# ISD91200B_v1 register map
File version: 1.0
Registers are 32-bit, read-write, reset 0x0 unless marked. A register's access mark holds for its fields unless they carry their own. Offsets are from the block's base; [hi:lo] are bit positions; {n}, {i} and the like mark numbered series; 'fields as' and 'values as' point back to an identical list.

## SARADC — SARADC Register Map
Base 0x40060000
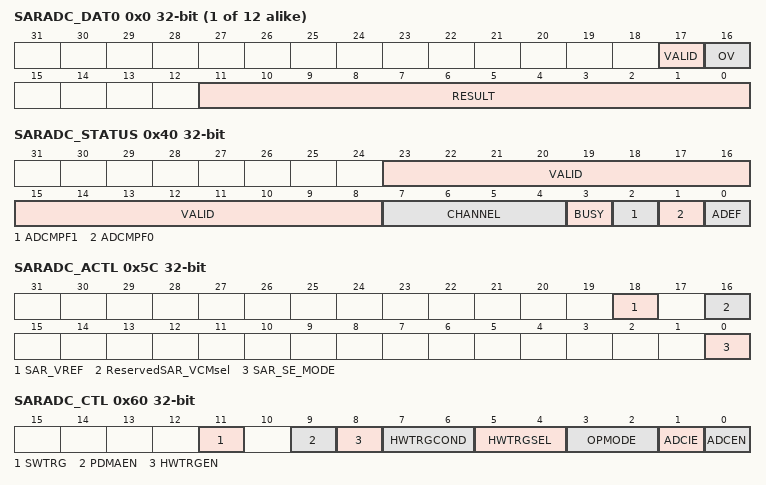
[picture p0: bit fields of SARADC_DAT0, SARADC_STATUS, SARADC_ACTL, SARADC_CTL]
{0x0+4i} SARADC_DAT{i} ro (i=0..11) — SAR ADC Data Register {i}
  [17] VALID — Valid Flag (Read Only). Note: This bit is set to 1 when corresponding channel analog input conversion is completed and cleared by hardware after DAT register is read.
    0=Data in RESULT[11:0] bits is not valid; 1=Data in RESULT[11:0] bits is valid
  [16] OV — Overrun Flag (Read Only). Note: If converted data in RESULT[11:0] has not been read before new conversion result is loaded to this register, OV is set to 1 and previous conversion result is gone. It is cleared by hardware after DAT register is read.
    0=Data in RESULT[11:0] is recent conversion result; 1=Data in RESULT[11:0] is overwritten
  [11:0] RESULT — A/D Conversion Result. This field contains conversion result of SARADC. 12-bit SARADC conversion result with unsigned format.
0x40 SARADC_STATUS
  [23:8] VALID ro — Data Valid Flag (Read Only). It is a mirror of VALID bit in DATx.
  [7:4] CHANNEL ro — Current Conversion Channel (Read Only)
  [3] BUSY ro — BUSY/IDLE (Read Only). This bit is mirror of as SWTRG bit in CTL.
    0=A/D converter is in idle state; 1=A/D converter is busy at conversion
  [2] ADCMPF1 — Compare Flag. When the selected channel A/D conversion result meets setting condition in SARADC_CMP1 then this bit is set to 1. And it is cleared by writing 1 to self.
    0=Conversion result in DAT register does not meet CMP1 register; 1=Conversion result in DAT register meets CMP1 register
  [1] ADCMPF0 — Compare Flag. When the selected channel A/D conversion result meets setting condition in SARADC_CMP0 then this bit is set to 1. And it is cleared by writing 1 to self.
    0=Conversion result in DAT register does not meet CMP0 register; 1=Conversion result in DAT register meets CMP0 register
  [0] ADEF — A/D Conversion End Flag. A status flag that indicates the end of A/D conversion. ADEF is set to 1 at these two conditions: 1. When A/D conversion ends in Single mode. 2. When A/D conversion ends on all specified channels in Scan mode. Note: This bit can be cleared by writing '1' to it.
0x50 SARADC_PDMADAT ro — SAR ADC PDMA Current Transfer Data
  [17:0] DATA — SAR ADC PDMA Current Transfer Data Register (Read Only). When PDMA transferring, read this register can monitor current PDMA transfer data. Current PDMA transfer data is the content of DAT0 ~ DAT11.
0x5C SARADC_ACTL — SAR ADC Analog Control Register
  [18] SAR_VREF — VREF selection. 0 -- select VCCA as VREF. 1 -- select MICBIAS as VREF
  [16] ReservedSAR_VCMsel — ReservedSAR VCM voltage. 0---- select internal VCM. 1 --- select external VCM
  [0] SAR_SE_MODE — SE mode selection
    1=SARADC in single ended mode
0x60 SARADC_CTL — SAR ADC Control Register
  [11] SWTRG — A/D Conversion Start. SWTRG bit can be set to 1 from three sources: software, external pin STADC. SWTRG will be cleared to 0 by hardware automatically at the ends of single mode and single-cycle scan mode. In continuous scan mode, A/D conversion is continuously performed until software writes 0 to this bit or chip reset.
    0=Conversion stops and A/D converter enter idle state; 1=Conversion starts
  [9] PDMAEN — PDMA Transfer Enable Bit
    0=PDMA data transfer Disabled; 1=PDMA data transfer in DAT 0~11 Enabled
  [8] HWTRGEN — Hardware Trigger Enable Bit. Enable or disable triggering of A/D conversion by hardware (external STADC pin or PWM Center-aligned trigger). SARADC hardware trigger function is only supported in single-cycle scan mode. If hardware trigger mode, the SWTRG bit can be set to 1 by the selected hardware trigger source.
    0=Disabled; 1=Enabled
  [7:6] HWTRGCOND — External Trigger Condition. These two bits decide external pin STADC trigger event is level or edge. The signal must be kept at stable state at least 8 PCLKs for level trigger and 4 PCLKs at high and low state for edge trigger.
    0=Low level; 1=High level; 2=Falling edge; 3=Rising edge
  [5:4] HWTRGSEL — Hardware Trigger Source Selection. Software should disable TRGEN and SWTRG before change HWTRGSEL.
    0=A/D conversion is started by external STADC pin
  [3:2] OPMODE — A/D Converter Operation Mode. When changing the operation mode, software should disable SWTRG bit firstly.
    0=Single conversion; 2=Single-cycle scan; 3=Continuous scan
  [1] ADCIE — A/D Interrupt Enable Bit. A/D conversion end interrupt request is generated if ADCIE bit is set to 1.
    0=A/D interrupt function Disabled; 1=A/D interrupt function Enabled
  [0] ADCEN — A/D Converter Enable Bit. Before starting A/D conversion function, this bit should be set to 1. Clear it to 0 to disable A/D converter analog circuit for saving power consumption.
    0=Disabled; 1=Enabled
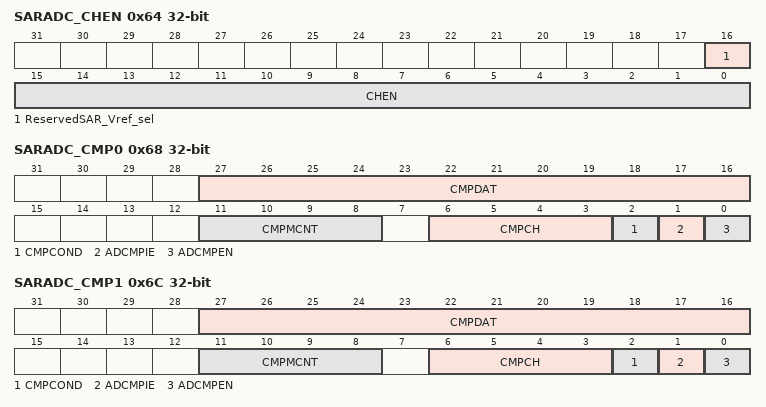
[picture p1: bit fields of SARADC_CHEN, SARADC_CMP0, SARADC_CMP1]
0x64 SARADC_CHEN — SAR ADC Channel Enable Register
  [16] ReservedSAR_Vref_sel — ReservedAnalog reference voltage. 0 --- use input [15] Note: no MUX selection to input[15] for user. 1 ---- measure voltage on vref_bandgap instead of voltage on input [15]
  [15:0] CHEN — Analog Input Channel Enable Bit. Set CHEN[11:0] to enable the corresponding analog input channel 11 ~ 0. Note: Keep 0 for [15:12]
    0=SARADC input channel Disabled; 1=SARADC input channel Enabled
0x68 SARADC_CMP0 — SAR ADC Compare Register 0
  [27:16] CMPDAT — Comparison Data. The 12-bit data is used to compare with conversion result of specified channel. When ADCFMbit is set to 0, SARADC comparator compares CMPDAT with conversion result with unsigned format. CMPDAT should be filled in unsigned format. When ADCFMbit is set to 1, SARADC comparator compares CMPDAT with conversion result with 2'complement format. CMPDAT should be filled in 2'complement format.
  [11:8] CMPMCNT — Compare Match Count. When the specified A/D channel analog conversion result matches the compare condition defined by CMPCOND[2], the internal match counter will increase 1. When the internal counter reaches the value to (CMPMCNT +1), the ADCMPFx bit will be set.
  [6:3] CMPCH — Compare Channel Selection
    {v}=Channel {v} conversion result is selected to be compared (v=0..11)
  [2] CMPCOND — Compare Condition. Note: When the internal counter reaches the value to (CMPMCNT +1), the ADCMPFx bit will be set.
    0=Set the compare condition as that when a 12-bit A/D conversion result is less than the 12-bit CMPDAT (CMPx[27:16]), the internal match counter will increase one; 1=Set the compare condition as that when a 12-bit A/D conversion result is greater or equal to the 12-bit CMPD (CMPx[27:16]), the internal match counter will increase one
  [1] ADCMPIE — Compare Interrupt Enable Bit. Note: If the compare function is enabled and the compare condition matches the setting of CMPCOND and CMPMCNT, ADCMPF bit will be asserted, in the meanwhile, if ADCMPIE is set to 1, a compare interrupt request is generated.
    0=Compare function interrupt Disabled; 1=Compare function interrupt Enabled
  [0] ADCMPEN — Compare Enable Bit. Note: Set this bit to 1 to enable SARADC controller to compare CMPDAT[11:0] with specified channel conversion result when converted data is loaded into DAT register.
    0=Compare function Disabled; 1=Compare function Enabled
0x6C SARADC_CMP1 — SAR ADC Compare Register 1
  fields as SARADC_CMP0
